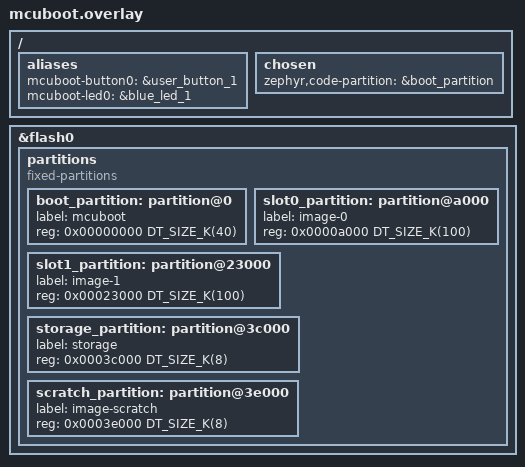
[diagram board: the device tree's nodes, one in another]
/{
    aliases{
        mcuboot-button0 = &user_button_1;
        mcuboot-led0 = &blue_led_1;
    };
    
    chosen {
        zephyr,code-partition = &boot_partition;
    };
};

/* 
 * Flash partition layout for STM32WL55JC (256KB total flash)
 * MCUboot bootloader starts at 0x08000000 (flash base address)
 * Layout: 40KB boot + 100KB slot0 + 100KB slot1 + 8KB storage + 8KB scratch = 256KB
 */
&flash0 {
    /* Delete existing partitions node to avoid conflicts */
    /delete-node/ partitions;
    
    partitions {
        compatible = "fixed-partitions";
        #address-cells = <1>;
        #size-cells = <1>;

        /* MCUboot bootloader - 40KB at base address */
        boot_partition: partition@0 {
            label = "mcuboot";
            reg = <0x00000000 DT_SIZE_K(40)>;
        };

        /* Primary application slot (slot0) - 100KB */
        slot0_partition: partition@a000 {
            label = "image-0";
            reg = <0x0000a000 DT_SIZE_K(100)>;
        };

        /* Secondary application slot (slot1) - 100KB */
        slot1_partition: partition@23000 {
            label = "image-1";
            reg = <0x00023000 DT_SIZE_K(100)>;
        };

        /* Storage for NVS (LoRaWAN settings) - 8KB */
        storage_partition: partition@3c000 {
            label = "storage";
            reg = <0x0003c000 DT_SIZE_K(8)>;
        };

        /* Scratch area for image swapping - 8KB */
        scratch_partition: partition@3e000 {
            label = "image-scratch";
            reg = <0x0003e000 DT_SIZE_K(8)>;
        };
    };
};

